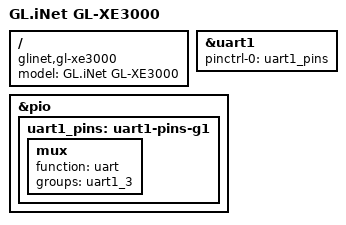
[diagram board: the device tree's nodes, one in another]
// SPDX-License-Identifier: GPL-2.0-or-later OR MIT

#include "mt7981a-glinet-gl-x3000-xe3000-common.dtsi"

/ {
	model = "GL.iNet GL-XE3000";
	compatible = "glinet,gl-xe3000", "mediatek,mt7981";
};

&uart1 {
	pinctrl-names = "default";
	pinctrl-0 = <&uart1_pins>;
	status = "okay";
};

&pio {
	uart1_pins: uart1-pins-g1 {
		mux {
			function = "uart";
			groups = "uart1_3";
		};
	};
};
